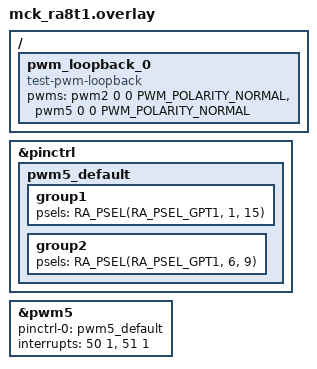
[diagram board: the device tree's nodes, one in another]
/*
 * Copyright (c) 2024 Renesas Electronics Corporation
 * SPDX-License-Identifier: Apache-2.0
 */

#include <zephyr/dt-bindings/pwm/pwm.h>
#include <zephyr/dt-bindings/pwm/ra_pwm.h>

/ {
	pwm_loopback_0 {
		compatible = "test-pwm-loopback";
		/* first index must be a 32-Bit timer */
		pwms = <&pwm2 0 0 PWM_POLARITY_NORMAL>,
			<&pwm5 0 0 PWM_POLARITY_NORMAL>;
	};
};

&pinctrl {
	pwm5_default: pwm5_default {
		group1 {
			/* GTIOC5A */
			psels = <RA_PSEL(RA_PSEL_GPT1, 1, 15)>;
		};
		group2 {
			/* GTIOC5B */
			psels = <RA_PSEL(RA_PSEL_GPT1, 6, 9)>;
		};
	};
};

&pwm5 {
	pinctrl-0 = <&pwm5_default>;
	pinctrl-names = "default";
	interrupts = <50 1>, <51 1>;
	interrupt-names = "gtioca", "overflow";
	status = "okay";
};
